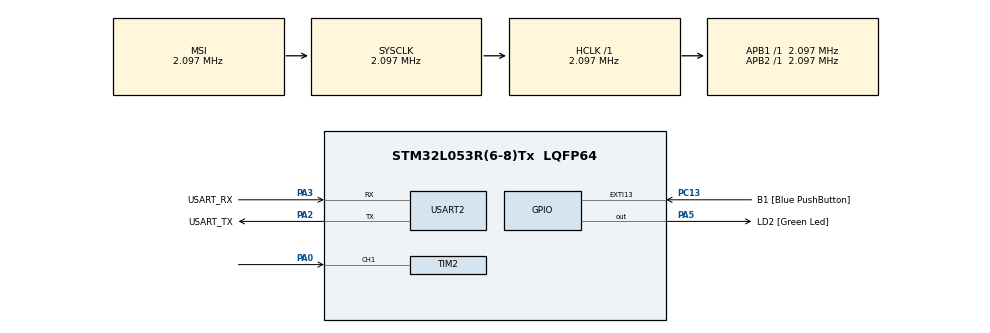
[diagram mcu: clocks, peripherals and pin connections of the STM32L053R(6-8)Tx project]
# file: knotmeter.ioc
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Dma.Request0=USART2_RX
Dma.Request1=USART2_TX
Dma.USART2_RX.0.Direction=DMA_PERIPH_TO_MEMORY
Dma.USART2_RX.0.Instance=DMA1_Channel5
Dma.USART2_RX.0.MemDataAlignment=DMA_MDATAALIGN_BYTE
Dma.USART2_RX.0.MemInc=DMA_MINC_ENABLE
Dma.USART2_RX.0.Mode=DMA_NORMAL
Dma.USART2_RX.0.PeriphDataAlignment=DMA_PDATAALIGN_BYTE
Dma.USART2_RX.0.PeriphInc=DMA_PINC_DISABLE
Dma.USART2_RX.0.Priority=DMA_PRIORITY_LOW
Dma.USART2_TX.1.Direction=DMA_MEMORY_TO_PERIPH
Dma.USART2_TX.1.Instance=DMA1_Channel4
Dma.USART2_TX.1.MemDataAlignment=DMA_MDATAALIGN_BYTE
Dma.USART2_TX.1.MemInc=DMA_MINC_ENABLE
Dma.USART2_TX.1.Mode=DMA_NORMAL
Dma.USART2_TX.1.PeriphDataAlignment=DMA_PDATAALIGN_BYTE
Dma.USART2_TX.1.PeriphInc=DMA_PINC_DISABLE
Dma.USART2_TX.1.Priority=DMA_PRIORITY_LOW
Mcu.Family=STM32L0
Mcu.Name=STM32L053R(6-8)Tx
Mcu.Package=LQFP64
NVIC.DMA1_Channel4_5_6_7_IRQn=true\:0\:0\:false\:false\:true\:false\:true
NVIC.USART2_IRQn=true\:0\:0\:false\:false\:true\:true\:true
PA0.Signal=S_TIM2_CH1
PA13.GPIO_Label=TMS
PA13.Mode=Serial_Wire
PA13.Signal=SYS_SWDIO
PA14.GPIO_Label=TCK
PA14.Mode=Serial_Wire
PA14.Signal=SYS_SWCLK
PA2.GPIO_Label=USART_TX
PA2.Mode=Asynchronous
PA2.Signal=USART2_TX
PA3.GPIO_Label=USART_RX
PA3.Mode=Asynchronous
PA3.Signal=USART2_RX
PA5.GPIO_Label=LD2 [Green Led]
PA5.Signal=GPIO_Output
PC13.GPIO_Label=B1 [Blue PushButton]
PC13.GPIO_ModeDefaultEXTI=GPIO_MODE_IT_FALLING
PC13.Signal=GPXTI13
PC14-OSC32_IN.Mode=LSE-External-Oscillator
PC14-OSC32_IN.Signal=RCC_OSC32_IN
PC15-OSC32_OUT.Mode=LSE-External-Oscillator
PC15-OSC32_OUT.Signal=RCC_OSC32_OUT
PH0-OSC_IN.Mode=HSE-External-Clock-Source
PH0-OSC_IN.Signal=RCC_OSC_IN
PH1-OSC_OUT.Signal=RCC_OSC_OUT
ProjectManager.HeapSize=0x0
ProjectManager.StackSize=0x400
ProjectManager.TargetToolchain=STM32CubeIDE
RCC.AHBFreq_Value=2097000
RCC.APB1Freq_Value=2097000
RCC.APB1TimFreq_Value=2097000
RCC.APB2Freq_Value=2097000
RCC.APB2TimFreq_Value=2097000
RCC.HSE_VALUE=8000000
RCC.HSI16_VALUE=16000000
RCC.HSI48_VALUE=48000000
RCC.HSI_VALUE=16000000
RCC.MSI_VALUE=2097000
RCC.SYSCLKFreq_VALUE=2097000
RCC.VCOOutputFreq_Value=48000000
SH.S_TIM2_CH1.0=TIM2_CH1,Input_Capture1_from_TI1
TIM2.Channel-Input_Capture1_from_TI1=TIM_CHANNEL_1
TIM2.Period=16000
TIM2.Prescaler=8000
USART2.VirtualMode-Asynchronous=VM_ASYNC
VP_TIM2_VS_ClockSourceINT.Mode=Internal
board=NUCLEO-L053R8

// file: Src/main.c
/* USER CODE BEGIN Header */
/**
  ******************************************************************************
  * @file           : main.c
  * @brief          : Main program body
  ******************************************************************************
  * @attention
  *
  * <h2><center>&copy; Copyright (c) 2020 STMicroelectronics.
  * All rights reserved.</center></h2>
  *
  * This software component is licensed by ST under BSD 3-Clause license,
  * the "License"; You may not use this file except in compliance with the
  * License. You may obtain a copy of the License at:
  *                        opensource.org/licenses/BSD-3-Clause
  *
  ******************************************************************************
  */
/* USER CODE END Header */
#include "main.h"

/* USER CODE BEGIN Includes */
#include "processorGlobal.h"
/* USER CODE END Includes */

TIM_HandleTypeDef htim2;

UART_HandleTypeDef huart2;
DMA_HandleTypeDef hdma_usart2_rx;
DMA_HandleTypeDef hdma_usart2_tx;

void SystemClock_Config(void);
static void MX_GPIO_Init(void);
static void MX_DMA_Init(void);
static void MX_USART2_UART_Init(void);
static void MX_TIM2_Init(void);
/* USER CODE BEGIN PFP */
void runApp(void);
/* USER CODE END PFP */

/* USER CODE BEGIN 0 */
UART_HandleTypeDef *usartHandler(uint8_t num) {
	if(num == 2) {
		return &huart2;
	}
	return NULL;
}
TIM_HandleTypeDef *timHandler(uint8_t num) {
	if(num == 2) {
		return &htim2;
	}
	return NULL;
}
/* USER CODE END 0 */

int main(void)
{

  /* MCU Configuration--------------------------------------------------------*/

  /* Reset of all peripherals, Initializes the Flash interface and the Systick. */
  HAL_Init();

  /* Configure the system clock */
  SystemClock_Config();

  /* Initialize all configured peripherals */
  MX_GPIO_Init();
  MX_DMA_Init();
  MX_USART2_UART_Init();
  MX_TIM2_Init();

  /* Infinite loop */
  /* USER CODE BEGIN WHILE */
  while (1)
  {
	  runApp();
    /* USER CODE END WHILE */

  }
}

void SystemClock_Config(void)
{
  RCC_OscInitTypeDef RCC_OscInitStruct = {0};
  RCC_ClkInitTypeDef RCC_ClkInitStruct = {0};
  RCC_PeriphCLKInitTypeDef PeriphClkInit = {0};

  /** Configure the main internal regulator output voltage
  */
  __HAL_PWR_VOLTAGESCALING_CONFIG(PWR_REGULATOR_VOLTAGE_SCALE1);
  /** Initializes the RCC Oscillators according to the specified parameters
  * in the RCC_OscInitTypeDef structure.
  */
  RCC_OscInitStruct.OscillatorType = RCC_OSCILLATORTYPE_MSI;
  RCC_OscInitStruct.MSIState = RCC_MSI_ON;
  RCC_OscInitStruct.MSICalibrationValue = 0;
  RCC_OscInitStruct.MSIClockRange = RCC_MSIRANGE_5;
  RCC_OscInitStruct.PLL.PLLState = RCC_PLL_NONE;
  if (HAL_RCC_OscConfig(&RCC_OscInitStruct) != HAL_OK)
  {
    Error_Handler();
  }
  /** Initializes the CPU, AHB and APB buses clocks
  */
  RCC_ClkInitStruct.ClockType = RCC_CLOCKTYPE_HCLK|RCC_CLOCKTYPE_SYSCLK
                              |RCC_CLOCKTYPE_PCLK1|RCC_CLOCKTYPE_PCLK2;
  RCC_ClkInitStruct.SYSCLKSource = RCC_SYSCLKSOURCE_MSI;
  RCC_ClkInitStruct.AHBCLKDivider = RCC_SYSCLK_DIV1;
  RCC_ClkInitStruct.APB1CLKDivider = RCC_HCLK_DIV1;
  RCC_ClkInitStruct.APB2CLKDivider = RCC_HCLK_DIV1;

  if (HAL_RCC_ClockConfig(&RCC_ClkInitStruct, FLASH_LATENCY_0) != HAL_OK)
  {
    Error_Handler();
  }
  PeriphClkInit.PeriphClockSelection = RCC_PERIPHCLK_USART2;
  PeriphClkInit.Usart2ClockSelection = RCC_USART2CLKSOURCE_PCLK1;
  if (HAL_RCCEx_PeriphCLKConfig(&PeriphClkInit) != HAL_OK)
  {
    Error_Handler();
  }
}

static void MX_TIM2_Init(void)
{

  TIM_ClockConfigTypeDef sClockSourceConfig = {0};
  TIM_MasterConfigTypeDef sMasterConfig = {0};
  TIM_IC_InitTypeDef sConfigIC = {0};

  htim2.Instance = TIM2;
  htim2.Init.Prescaler = 8000;
  htim2.Init.CounterMode = TIM_COUNTERMODE_UP;
  htim2.Init.Period = 16000;
  htim2.Init.ClockDivision = TIM_CLOCKDIVISION_DIV1;
  htim2.Init.AutoReloadPreload = TIM_AUTORELOAD_PRELOAD_DISABLE;
  if (HAL_TIM_Base_Init(&htim2) != HAL_OK)
  {
    Error_Handler();
  }
  sClockSourceConfig.ClockSource = TIM_CLOCKSOURCE_INTERNAL;
  if (HAL_TIM_ConfigClockSource(&htim2, &sClockSourceConfig) != HAL_OK)
  {
    Error_Handler();
  }
  if (HAL_TIM_IC_Init(&htim2) != HAL_OK)
  {
    Error_Handler();
  }
  sMasterConfig.MasterOutputTrigger = TIM_TRGO_RESET;
  sMasterConfig.MasterSlaveMode = TIM_MASTERSLAVEMODE_DISABLE;
  if (HAL_TIMEx_MasterConfigSynchronization(&htim2, &sMasterConfig) != HAL_OK)
  {
    Error_Handler();
  }
  sConfigIC.ICPolarity = TIM_INPUTCHANNELPOLARITY_RISING;
  sConfigIC.ICSelection = TIM_ICSELECTION_DIRECTTI;
  sConfigIC.ICPrescaler = TIM_ICPSC_DIV1;
  sConfigIC.ICFilter = 0;
  if (HAL_TIM_IC_ConfigChannel(&htim2, &sConfigIC, TIM_CHANNEL_1) != HAL_OK)
  {
    Error_Handler();
  }

}

static void MX_USART2_UART_Init(void)
{

  huart2.Instance = USART2;
  huart2.Init.BaudRate = 115200;
  huart2.Init.WordLength = UART_WORDLENGTH_8B;
  huart2.Init.StopBits = UART_STOPBITS_1;
  huart2.Init.Parity = UART_PARITY_NONE;
  huart2.Init.Mode = UART_MODE_TX_RX;
  huart2.Init.HwFlowCtl = UART_HWCONTROL_NONE;
  huart2.Init.OverSampling = UART_OVERSAMPLING_16;
  huart2.Init.OneBitSampling = UART_ONE_BIT_SAMPLE_DISABLE;
  huart2.AdvancedInit.AdvFeatureInit = UART_ADVFEATURE_NO_INIT;
  if (HAL_UART_Init(&huart2) != HAL_OK)
  {
    Error_Handler();
  }

}

static void MX_DMA_Init(void)
{

  /* DMA controller clock enable */
  __HAL_RCC_DMA1_CLK_ENABLE();

  /* DMA interrupt init */
  /* DMA1_Channel4_5_6_7_IRQn interrupt configuration */
  HAL_NVIC_SetPriority(DMA1_Channel4_5_6_7_IRQn, 0, 0);
  HAL_NVIC_EnableIRQ(DMA1_Channel4_5_6_7_IRQn);

}

static void MX_GPIO_Init(void)
{
  GPIO_InitTypeDef GPIO_InitStruct = {0};

  /* GPIO Ports Clock Enable */
  __HAL_RCC_GPIOC_CLK_ENABLE();
  __HAL_RCC_GPIOH_CLK_ENABLE();
  __HAL_RCC_GPIOA_CLK_ENABLE();

  /*Configure GPIO pin Output Level */
  HAL_GPIO_WritePin(LD2_GPIO_Port, LD2_Pin, GPIO_PIN_RESET);

  /*Configure GPIO pin : B1_Pin */
  GPIO_InitStruct.Pin = B1_Pin;
  GPIO_InitStruct.Mode = GPIO_MODE_IT_FALLING;
  GPIO_InitStruct.Pull = GPIO_NOPULL;
  HAL_GPIO_Init(B1_GPIO_Port, &GPIO_InitStruct);

  /*Configure GPIO pin : LD2_Pin */
  GPIO_InitStruct.Pin = LD2_Pin;
  GPIO_InitStruct.Mode = GPIO_MODE_OUTPUT_PP;
  GPIO_InitStruct.Pull = GPIO_NOPULL;
  GPIO_InitStruct.Speed = GPIO_SPEED_FREQ_LOW;
  HAL_GPIO_Init(LD2_GPIO_Port, &GPIO_InitStruct);

}

void Error_Handler(void)
{
}

/************************ (C) COPYRIGHT STMicroelectronics *****END OF FILE****/
